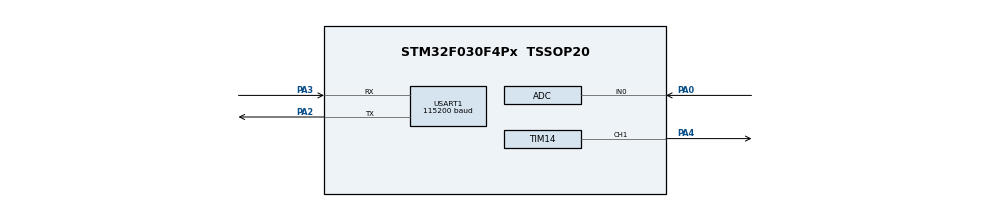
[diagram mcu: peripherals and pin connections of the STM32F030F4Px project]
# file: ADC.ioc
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ADC.ContinuousConvMode=ENABLE
Mcu.Family=STM32F0
Mcu.Name=STM32F030F4Px
Mcu.Package=TSSOP20
NVIC.ADC1_IRQn=true\:0\:0\:false\:false\:true\:true
NVIC.USART1_IRQn=true\:0\:0\:false\:false\:true\:true
PA0.Mode=IN0
PA0.Signal=ADC_IN0
PA2.Mode=Asynchronous
PA2.Signal=USART1_TX
PA3.Mode=Asynchronous
PA3.Signal=USART1_RX
PA4.GPIO_Speed=GPIO_SPEED_FREQ_HIGH
PA4.Signal=S_TIM14_CH1
ProjectManager.HeapSize=0x200
ProjectManager.StackSize=0x400
ProjectManager.TargetToolchain=MDK-ARM V5
SH.S_TIM14_CH1.0=TIM14_CH1,PWM Generation1 CH1
TIM14.Channel=TIM_CHANNEL_1
TIM14.Period=4
TIM14.Prescaler=1
TIM14.Pulse=2
USART1.BaudRate=115200
USART1.VirtualMode-Asynchronous=VM_ASYNC
VP_TIM14_VS_ClockSourceINT.Mode=Enable_Timer
board=ADC

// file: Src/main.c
/**
  ******************************************************************************
  * File Name          : main.c
  * Description        : Main program body
  ******************************************************************************
  ** This notice applies to any and all portions of this file
  * that are not between comment pairs USER CODE BEGIN and
  * USER CODE END. Other portions of this file, whether
  * inserted by the user or by software development tools
  * are owned by their respective copyright owners.
  *
  * COPYRIGHT(c) 2020 STMicroelectronics
  *
  * Redistribution and use in source and binary forms, with or without modification,
  * are permitted provided that the following conditions are met:
  *   1. Redistributions of source code must retain the above copyright notice,
  *      this list of conditions and the following disclaimer.
  *   2. Redistributions in binary form must reproduce the above copyright notice,
  *      this list of conditions and the following disclaimer in the documentation
  *      and/or other materials provided with the distribution.
  *   3. Neither the name of STMicroelectronics nor the names of its contributors
  *      may be used to endorse or promote products derived from this software
  *      without specific prior written permission.
  *
  * THIS SOFTWARE IS PROVIDED BY THE COPYRIGHT HOLDERS AND CONTRIBUTORS "AS IS"
  * AND ANY EXPRESS OR IMPLIED WARRANTIES, INCLUDING, BUT NOT LIMITED TO, THE
  * IMPLIED WARRANTIES OF MERCHANTABILITY AND FITNESS FOR A PARTICULAR PURPOSE ARE
  * DISCLAIMED. IN NO EVENT SHALL THE COPYRIGHT HOLDER OR CONTRIBUTORS BE LIABLE
  * FOR ANY DIRECT, INDIRECT, INCIDENTAL, SPECIAL, EXEMPLARY, OR CONSEQUENTIAL
  * DAMAGES (INCLUDING, BUT NOT LIMITED TO, PROCUREMENT OF SUBSTITUTE GOODS OR
  * SERVICES; LOSS OF USE, DATA, OR PROFITS; OR BUSINESS INTERRUPTION) HOWEVER
  * CAUSED AND ON ANY THEORY OF LIABILITY, WHETHER IN CONTRACT, STRICT LIABILITY,
  * OR TORT (INCLUDING NEGLIGENCE OR OTHERWISE) ARISING IN ANY WAY OUT OF THE USE
  * OF THIS SOFTWARE, EVEN IF ADVISED OF THE POSSIBILITY OF SUCH DAMAGE.
  *
  ******************************************************************************
  */

#include "main.h"
#include "stm32f0xx_hal.h"

ADC_HandleTypeDef hadc;

TIM_HandleTypeDef htim14;

UART_HandleTypeDef huart1;

/* USER CODE BEGIN PV */
/* Private variables ---------------------------------------------------------*/

/* USER CODE END PV */

void SystemClock_Config(void);
static void MX_GPIO_Init(void);
static void MX_ADC_Init(void);
static void MX_USART1_UART_Init(void);
static void MX_TIM14_Init(void);

void HAL_TIM_MspPostInit(TIM_HandleTypeDef *htim);

/* USER CODE BEGIN PFP */
/* Private function prototypes -----------------------------------------------*/

/* USER CODE END PFP */

int main(void)
{

  /* MCU Configuration----------------------------------------------------------*/

  /* Reset of all peripherals, Initializes the Flash interface and the Systick. */
  HAL_Init();

  /* Configure the system clock */
  SystemClock_Config();

  /* Initialize all configured peripherals */
  MX_GPIO_Init();
  MX_ADC_Init();
  MX_USART1_UART_Init();
  MX_TIM14_Init();

  /* USER CODE BEGIN 2 */
	HAL_ADC_Start(&hadc);
	HAL_TIM_PWM_Start(&htim14, TIM_CHANNEL_1);
  /* USER CODE END 2 */

  /* Infinite loop */
  while (1)
  {

  /* USER CODE BEGIN 3 */

		if (HAL_ADC_PollForConversion(&hadc, 1000000) == HAL_OK) {
			uint16_t adcResult = HAL_ADC_GetValue(&hadc);
			char data[8] = {0};
			sprintf(data, "%d\n", adcResult);
			HAL_UART_Transmit(&huart1, (uint8_t*)data, 8, HAL_MAX_DELAY);
			HAL_Delay(500);
		}
  }
	//HAL_ADC_Stop(&hadc);

  /* USER CODE END 3 */

}
#include <string.h>
/** System Clock Configuration
*/
void SystemClock_Config(void)
{

  RCC_OscInitTypeDef RCC_OscInitStruct;
  RCC_ClkInitTypeDef RCC_ClkInitStruct;
  RCC_PeriphCLKInitTypeDef PeriphClkInit;

    /**Initializes the CPU, AHB and APB busses clocks
    */
  RCC_OscInitStruct.OscillatorType = RCC_OSCILLATORTYPE_HSI|RCC_OSCILLATORTYPE_HSI14;
  RCC_OscInitStruct.HSIState = RCC_HSI_ON;
  RCC_OscInitStruct.HSI14State = RCC_HSI14_ON;
  RCC_OscInitStruct.HSICalibrationValue = 16;
  RCC_OscInitStruct.HSI14CalibrationValue = 16;
  RCC_OscInitStruct.PLL.PLLState = RCC_PLL_NONE;
  if (HAL_RCC_OscConfig(&RCC_OscInitStruct) != HAL_OK)
  {
    _Error_Handler(__FILE__, __LINE__);
  }

    /**Initializes the CPU, AHB and APB busses clocks
    */
  RCC_ClkInitStruct.ClockType = RCC_CLOCKTYPE_HCLK|RCC_CLOCKTYPE_SYSCLK
                              |RCC_CLOCKTYPE_PCLK1;
  RCC_ClkInitStruct.SYSCLKSource = RCC_SYSCLKSOURCE_HSI;
  RCC_ClkInitStruct.AHBCLKDivider = RCC_SYSCLK_DIV1;
  RCC_ClkInitStruct.APB1CLKDivider = RCC_HCLK_DIV1;

  if (HAL_RCC_ClockConfig(&RCC_ClkInitStruct, FLASH_LATENCY_0) != HAL_OK)
  {
    _Error_Handler(__FILE__, __LINE__);
  }

  PeriphClkInit.PeriphClockSelection = RCC_PERIPHCLK_USART1;
  PeriphClkInit.Usart1ClockSelection = RCC_USART1CLKSOURCE_PCLK1;
  if (HAL_RCCEx_PeriphCLKConfig(&PeriphClkInit) != HAL_OK)
  {
    _Error_Handler(__FILE__, __LINE__);
  }

    /**Configure the Systick interrupt time
    */
  HAL_SYSTICK_Config(HAL_RCC_GetHCLKFreq()/1000);

    /**Configure the Systick
    */
  HAL_SYSTICK_CLKSourceConfig(SYSTICK_CLKSOURCE_HCLK);

  /* SysTick_IRQn interrupt configuration */
  HAL_NVIC_SetPriority(SysTick_IRQn, 0, 0);
}

/* ADC init function */
static void MX_ADC_Init(void)
{

  ADC_ChannelConfTypeDef sConfig;

    /**Configure the global features of the ADC (Clock, Resolution, Data Alignment and number of conversion)
    */
  hadc.Instance = ADC1;
  hadc.Init.ClockPrescaler = ADC_CLOCK_ASYNC_DIV1;
  hadc.Init.Resolution = ADC_RESOLUTION_12B;
  hadc.Init.DataAlign = ADC_DATAALIGN_RIGHT;
  hadc.Init.ScanConvMode = ADC_SCAN_DIRECTION_FORWARD;
  hadc.Init.EOCSelection = ADC_EOC_SINGLE_CONV;
  hadc.Init.LowPowerAutoWait = DISABLE;
  hadc.Init.LowPowerAutoPowerOff = DISABLE;
  hadc.Init.ContinuousConvMode = ENABLE;
  hadc.Init.DiscontinuousConvMode = DISABLE;
  hadc.Init.ExternalTrigConv = ADC_SOFTWARE_START;
  hadc.Init.ExternalTrigConvEdge = ADC_EXTERNALTRIGCONVEDGE_NONE;
  hadc.Init.DMAContinuousRequests = DISABLE;
  hadc.Init.Overrun = ADC_OVR_DATA_PRESERVED;
  if (HAL_ADC_Init(&hadc) != HAL_OK)
  {
    _Error_Handler(__FILE__, __LINE__);
  }

    /**Configure for the selected ADC regular channel to be converted.
    */
  sConfig.Channel = ADC_CHANNEL_0;
  sConfig.Rank = ADC_RANK_CHANNEL_NUMBER;
  sConfig.SamplingTime = ADC_SAMPLETIME_1CYCLE_5;
  if (HAL_ADC_ConfigChannel(&hadc, &sConfig) != HAL_OK)
  {
    _Error_Handler(__FILE__, __LINE__);
  }

}

/* TIM14 init function */
static void MX_TIM14_Init(void)
{

  TIM_OC_InitTypeDef sConfigOC;

  htim14.Instance = TIM14;
  htim14.Init.Prescaler = 1;
  htim14.Init.CounterMode = TIM_COUNTERMODE_UP;
  htim14.Init.Period = 4;
  htim14.Init.ClockDivision = TIM_CLOCKDIVISION_DIV1;
  htim14.Init.AutoReloadPreload = TIM_AUTORELOAD_PRELOAD_DISABLE;
  if (HAL_TIM_Base_Init(&htim14) != HAL_OK)
  {
    _Error_Handler(__FILE__, __LINE__);
  }

  if (HAL_TIM_PWM_Init(&htim14) != HAL_OK)
  {
    _Error_Handler(__FILE__, __LINE__);
  }

  sConfigOC.OCMode = TIM_OCMODE_PWM1;
  sConfigOC.Pulse = 2;
  sConfigOC.OCPolarity = TIM_OCPOLARITY_HIGH;
  sConfigOC.OCFastMode = TIM_OCFAST_DISABLE;
  if (HAL_TIM_PWM_ConfigChannel(&htim14, &sConfigOC, TIM_CHANNEL_1) != HAL_OK)
  {
    _Error_Handler(__FILE__, __LINE__);
  }

  HAL_TIM_MspPostInit(&htim14);

}

/* USART1 init function */
static void MX_USART1_UART_Init(void)
{

  huart1.Instance = USART1;
  huart1.Init.BaudRate = 115200;
  huart1.Init.WordLength = UART_WORDLENGTH_8B;
  huart1.Init.StopBits = UART_STOPBITS_1;
  huart1.Init.Parity = UART_PARITY_NONE;
  huart1.Init.Mode = UART_MODE_TX_RX;
  huart1.Init.HwFlowCtl = UART_HWCONTROL_NONE;
  huart1.Init.OverSampling = UART_OVERSAMPLING_16;
  huart1.Init.OneBitSampling = UART_ONE_BIT_SAMPLE_DISABLE;
  huart1.AdvancedInit.AdvFeatureInit = UART_ADVFEATURE_NO_INIT;
  if (HAL_UART_Init(&huart1) != HAL_OK)
  {
    _Error_Handler(__FILE__, __LINE__);
  }

}

/** Pinout Configuration
*/
static void MX_GPIO_Init(void)
{

  /* GPIO Ports Clock Enable */
  __HAL_RCC_GPIOA_CLK_ENABLE();

}

void _Error_Handler(char * file, int line)
{
  while(1)
  {
  }
}

/************************ (C) COPYRIGHT STMicroelectronics *****END OF FILE****/
